CM_ "IMPORT _honda_common.dbc";
CM_ "IMPORT _bosch_2023_odyssey.dbc";
CM_ "IMPORT _steering_sensors_b.dbc";
CM_ "IMPORT _gearbox_common.dbc";
CM_ "IMPORT _nidec_scm_group_a.dbc";
CM_ "IMPORT _lkas_hud_8byte.dbc";
CM_ "IMPORT _bosch_standstill.dbc";

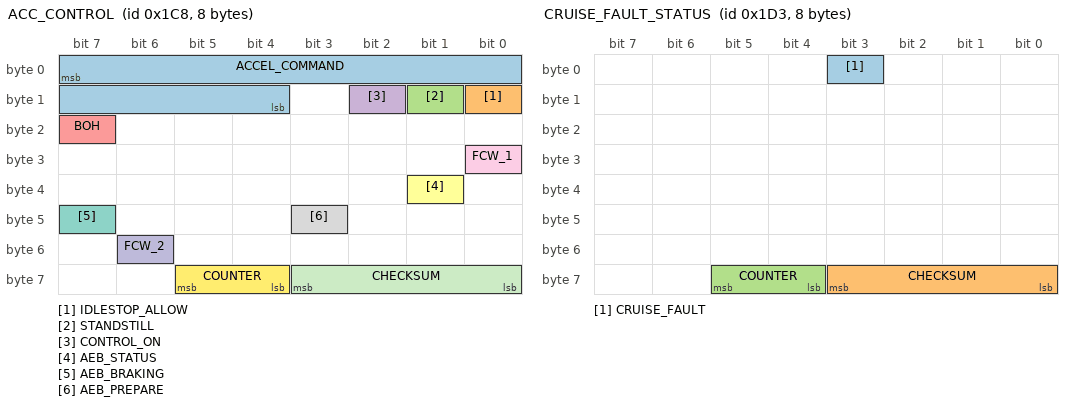
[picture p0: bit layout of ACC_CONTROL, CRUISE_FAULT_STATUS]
BO_ 456 ACC_CONTROL: 8 XXX
 SG_ ACCEL_COMMAND : 7|12@0- (0.01,0) [0|0] "m/s^2" XXX
 SG_ IDLESTOP_ALLOW : 8|1@0+ (1,0) [0|1] "" XXX
 SG_ STANDSTILL : 9|1@0+ (1,0) [0|1] "" XXX
 SG_ CONTROL_ON : 10|1@0+ (1,0) [0|1] "" XXX
 SG_ BOH : 23|1@0+ (1,0) [0|1] "" XXX
 SG_ AEB_STATUS : 33|1@1+ (1,0) [0|7] "" XXX
 SG_ AEB_BRAKING : 47|1@0+ (1,0) [0|1] "" XXX
 SG_ AEB_PREPARE : 43|1@0+ (1,0) [0|1] "" XXX
 SG_ FCW_1 : 24|1@1+ (1,0) [0|3] "" XXX
 SG_ FCW_2 : 54|1@0+ (1,0) [0|3] "" XXX
 SG_ CHECKSUM : 59|4@0+ (1,0) [0|15] "" XXX
 SG_ COUNTER : 61|2@0+ (1,0) [0|3] "" XXX

BO_ 467 CRUISE_FAULT_STATUS: 8 XXX
 SG_ CRUISE_FAULT : 3|1@0+ (1,0) [0|1] "" XXX
 SG_ CHECKSUM : 59|4@0+ (1,0) [0|15] "" XXX
 SG_ COUNTER : 61|2@0+ (1,0) [0|3] "" XXX

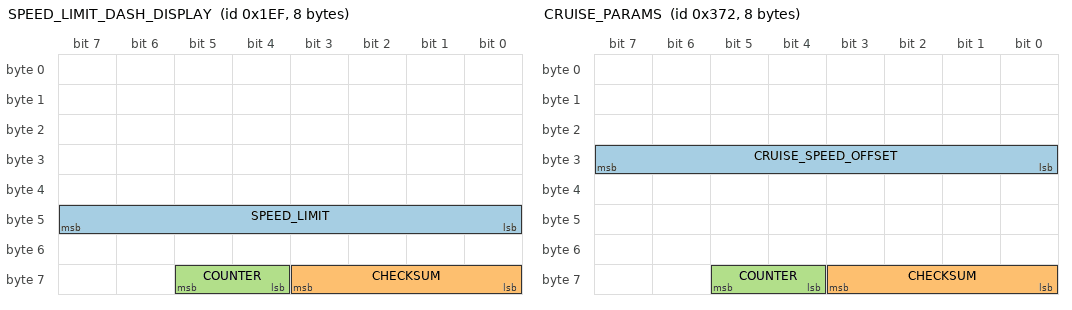
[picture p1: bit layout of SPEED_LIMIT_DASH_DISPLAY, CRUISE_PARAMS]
BO_ 495 SPEED_LIMIT_DASH_DISPLAY: 8 ADAS
 SG_ SPEED_LIMIT : 47|8@0+ (1,0) [0|255] "mph" XXX
 SG_ CHECKSUM : 59|4@0+ (1,0) [0|15] "" XXX
 SG_ COUNTER : 61|2@0+ (1,0) [0|3] "" XXX

BO_ 882 CRUISE_PARAMS: 8 PCM
 SG_ CRUISE_SPEED_OFFSET : 31|8@0- (0.1,0) [-128|127] "kph" EON
 SG_ CHECKSUM : 59|4@0+ (1,0) [0|3] "" EON
 SG_ COUNTER : 61|2@0+ (1,0) [0|15] "" EON

CM_ SG_ 456 IDLESTOP_ALLOW "allows car to turn off engine at a standstill";
CM_ SG_ 456 STANDSTILL "set to 1 when camera requests -4.0 m/s^2";
CM_ SG_ 495 SPEED_LIMIT "Defaults to 0xFF if no speed limit found";

VAL_ 477 GEAR_MT 14 "reverse" 6 "6th" 5 "5th" 4 "4th" 3 "3rd" 2 "2nd" 1 "1st" 0 "Clutch";
